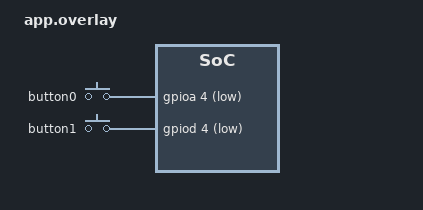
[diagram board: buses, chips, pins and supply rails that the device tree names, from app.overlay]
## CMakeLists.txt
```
# SPDX-License-Identifier: Apache-2.0
cmake_minimum_required(VERSION 3.20.0)
find_package(Zephyr REQUIRED HINTS $ENV{ZEPHYR_BASE})
project(kg100s_lorawan)
zephyr_include_directories(src)
target_sources(app PRIVATE src/main.c src/telemetry.c src/telemetry_packet.c src/join_policy.c
                          src/ble_event.c src/ble_bridge.c)
```

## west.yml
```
# SPDX-License-Identifier: Apache-2.0
manifest:
  version: '1.2'
  projects:
    - name: zephyr
      url: https://github.com/zephyrproject-rtos/zephyr
      revision: 41d10b59730406bbab4ca9f1fbbe9e96aafb4966
      import:
        name-allowlist: [cmsis, cmsis_6, hal_silabs, loramac-node, segger,
                         mbedtls, tf-psa-crypto, tf-psa-crypto-drivers]
  self:
    path: app
```

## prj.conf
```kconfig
# SPDX-License-Identifier: Apache-2.0
CONFIG_LORA=y
CONFIG_LORA_MODULE_BACKEND_LORAMAC_NODE=y
CONFIG_LORAWAN=y
CONFIG_LORAWAN_REGION_US915=y
CONFIG_LORAWAN_NVM_NONE=y

CONFIG_FLASH=y
CONFIG_FLASH_MAP=y
CONFIG_NVS=y
CONFIG_NVS_DATA_CRC=y
CONFIG_SETTINGS=y
CONFIG_SETTINGS_NVS=y
CONFIG_USE_DT_CODE_PARTITION=y

CONFIG_SHELL=y
CONFIG_SHELL_BACKEND_SERIAL=y
CONFIG_SHELL_PROMPT_UART="kg100s> "
CONFIG_SHELL_ECHO_STATUS=n
CONFIG_SHELL_VT100_COLORS=n
CONFIG_SHELL_VT100_COMMANDS=n
CONFIG_SHELL_HISTORY=n
CONFIG_SHELL_CMD_BUFF_SIZE=160
CONFIG_SHELL_STACK_SIZE=3072
CONFIG_LOG=y
CONFIG_LOG_DEFAULT_LEVEL=3
CONFIG_LOG_BACKEND_UART=n
CONFIG_LOG_MODE_IMMEDIATE=y
CONFIG_MAIN_STACK_SIZE=4096
CONFIG_SYSTEM_WORKQUEUE_STACK_SIZE=2048
CONFIG_HEAP_MEM_POOL_SIZE=4096
CONFIG_REBOOT=y
CONFIG_BOOT_BANNER=y
CONFIG_BUILD_OUTPUT_HEX=y
CONFIG_BT=y
CONFIG_BT_PERIPHERAL=y
CONFIG_BT_MAX_CONN=4
CONFIG_BT_SILABS_EFR32_BUFFER_MEMORY=12288
CONFIG_BT_DEVICE_NAME="OpenSidewalk"
CONFIG_BT_DIS=y
CONFIG_BT_DIS_MODEL_NUMBER_STR="KG100S BLE to TTN"
CONFIG_BT_DIS_MANUF_NAME_STR="OpenSidewalk"
CONFIG_SENSOR=y
CONFIG_INPUT=y
CONFIG_INPUT_GPIO_KEYS=y
```

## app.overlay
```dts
/* SPDX-License-Identifier: Apache-2.0 */
/* Standalone application; the factory demo has no MCUboot installation. */
/ {
	chosen {
		zephyr,code-partition = &app_partition;
	};
};

&flash0 {
	partitions {
		/delete-node/ partition@0;
		/delete-node/ partition@c000;
		/delete-node/ partition@82000;

		app_partition: partition@0 {
			compatible = "zephyr,mapped-partition";
			label = "application";
			reg = <0x00000000 0x000f8000>;
		};
		/* Existing 32 KiB storage partition at 0xf8000 holds NVS. */
	};
};

&button0 {
	gpios = <&gpioa 4 (GPIO_ACTIVE_LOW | GPIO_PULL_UP)>;
};

&button1 {
	gpios = <&gpiod 4 (GPIO_ACTIVE_LOW | GPIO_PULL_UP)>;
};
```

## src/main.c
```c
/* SPDX-License-Identifier: Apache-2.0 */
#include <errno.h>
#include <string.h>
#include <zephyr/device.h>
#include <zephyr/kernel.h>
#include <zephyr/lorawan/lorawan.h>
#include <zephyr/settings/settings.h>
#include <zephyr/shell/shell.h>
#include <zephyr/sys/atomic.h>
#include <zephyr/sys/util.h>
#include <zephyr/sys/reboot.h>
#include <zephyr/logging/log.h>
#include "telemetry.h"
#include "join_policy.h"
#include "ble_bridge.h"

LOG_MODULE_REGISTER(kg100s_lorawan, LOG_LEVEL_INF);

struct node_config {
	uint8_t version;
	uint8_t provisioned;
	uint8_t subband;
	uint8_t reserved;
	uint8_t dev_eui[8];
	uint8_t join_eui[8];
	uint8_t app_key[16];
	uint32_t last_nonce;
};

static struct node_config config = {.version = 1, .subband = 2};
static atomic_t ready;
static atomic_t joined;
static atomic_t busy;
static int config_load_error;
static uint16_t telemetry_sequence;
static int64_t next_periodic;
static int64_t telemetry_not_before;
static int64_t next_join;
static unsigned int join_failures;
static int64_t next_ble_attempt;
static atomic_t join_delay_seconds = ATOMIC_INIT(JOIN_BOOT_DELAY_MS / 1000);
K_MUTEX_DEFINE(config_lock);

enum job_kind { JOB_JOIN, JOB_SEND };
struct job {
	enum job_kind kind;
};
K_MSGQ_DEFINE(jobs, sizeof(struct job), 1, 4);

static int config_load(const char *name, size_t len, settings_read_cb read_cb, void *cb_arg)
{
	struct node_config saved;
	int ret;

	if (strcmp(name, "config") != 0) {
		return -ENOENT;
	}
	if (len != sizeof(saved)) {
		return config_load_error = -EINVAL;
	}
	ret = read_cb(cb_arg, &saved, sizeof(saved));
	if (ret != sizeof(saved)) {
		return config_load_error = ret < 0 ? ret : -EIO;
	}
	if (saved.version != 1 || saved.subband < 1 || saved.subband > 8 ||
	    saved.provisioned > 1 || saved.last_nonce > UINT16_MAX) {
		return config_load_error = -EINVAL;
	}
	config = saved;
	return 0;
}
SETTINGS_STATIC_HANDLER_DEFINE(kg100s_node, "kg100s", NULL, config_load, NULL, NULL);

static struct node_config config_snapshot(void)
{
	struct node_config copy;

	k_mutex_lock(&config_lock, K_FOREVER);
	copy = config;
	k_mutex_unlock(&config_lock);
	return copy;
}

static int save_config(const struct node_config *updated)
{
	int ret = settings_save_one("kg100s/config", updated, sizeof(*updated));

	if (ret == 0) {
		k_mutex_lock(&config_lock, K_FOREVER);
		config = *updated;
		k_mutex_unlock(&config_lock);
	}
	return ret;
}

static int cmd_status(const struct shell *sh, size_t argc, char **argv)
{
	struct node_config copy = config_snapshot();
	char dev_eui[17], join_eui[17];

	ARG_UNUSED(argc);
	ARG_UNUSED(argv);
	bin2hex(copy.dev_eui, sizeof(copy.dev_eui), dev_eui, sizeof(dev_eui));
	bin2hex(copy.join_eui, sizeof(copy.join_eui), join_eui, sizeof(join_eui));
	shell_print(sh, "KG100S BLE/LoRaWAN bridge v0.4.1; Zephyr 4.5.0");
	shell_print(sh, "Radio/stack: %s; joined: %s; busy: %s",
		    atomic_get(&ready) ? "ready" : "not ready",
		    atomic_get(&joined) ? "yes" : "no", atomic_get(&busy) ? "yes" : "no");
	shell_print(sh, "US915 sub-band %u: uplink channels %u-%u, 500kHz channel %u",
		    copy.subband, (copy.subband - 1) * 8, copy.subband * 8 - 1,
		    63 + copy.subband);
	shell_print(sh, "OTAA credentials: %s; DevEUI: %s; JoinEUI: %s",
		    copy.provisioned ? "configured" : "not configured", dev_eui, join_eui);
	shell_print(sh, "Last reserved DevNonce: %u; fresh OTAA joins automatically after reboot.",
		    (unsigned int)copy.last_nonce);
	if (atomic_get(&join_delay_seconds) < 0) {
		shell_print(sh, "Auto-join halted by configuration/storage error; check logs.");
	} else {
		shell_print(sh, "Auto-join enabled; last scheduled delay: %u seconds.",
			    (unsigned int)atomic_get(&join_delay_seconds));
	}
	return 0;
}

static int begin_config(const struct shell *sh)
{
	if (!atomic_cas(&busy, 0, 1)) {
		shell_error(sh, "Operation in progress.");
		return -EBUSY;
	}
	if (!atomic_get(&ready) || atomic_get(&joined)) {
		atomic_clear(&busy);
		shell_error(sh, "Radio not ready, operation in progress, or already joined. Reboot before changing a joined profile.");
		return -EBUSY;
	}
	return 0;
}

static int cmd_provision(const struct shell *sh, size_t argc, char **argv)
{
	struct node_config updated;
	uint8_t dev_eui[8], join_eui[8], app_key[16];
	int ret;

	ARG_UNUSED(argc);
	if (strlen(argv[1]) != 16 || strlen(argv[2]) != 16 || strlen(argv[3]) != 32 ||
	    hex2bin(argv[1], 16, dev_eui, 8) != 8 ||
	    hex2bin(argv[2], 16, join_eui, 8) != 8 ||
	    hex2bin(argv[3], 32, app_key, 16) != 16) {
		shell_error(sh, "Expected hexadecimal DevEUI (16), JoinEUI (16), AppKey (32). No colons.");
		return -EINVAL;
	}
	ret = begin_config(sh);
	if (ret) {
		return ret;
	}
	updated = config_snapshot();
	memcpy(updated.dev_eui, dev_eui, sizeof(dev_eui));
	memcpy(updated.join_eui, join_eui, sizeof(join_eui));
	memcpy(updated.app_key, app_key, sizeof(app_key));
	updated.provisioned = 1;
	ret = save_config(&updated);
	atomic_clear(&busy);
	if (ret) {
		shell_error(sh, "Saving credentials failed: %d", ret);
	} else {
		shell_print(sh, "OTAA credentials saved; AppKey is hidden. Register the same values on the network server, then run lw join.");
	}
	return ret;
}

static int cmd_subband(const struct shell *sh, size_t argc, char **argv)
{
	struct node_config updated;
	int ret;

	ARG_UNUSED(argc);
	if (strlen(argv[1]) != 1 || argv[1][0] < '1' || argv[1][0] > '8') {
		shell_error(sh, "Sub-band must be 1 through 8.");
		return -EINVAL;
	}
	ret = begin_config(sh);
	if (ret) {
		return ret;
	}
	updated = config_snapshot();
	updated.subband = argv[1][0] - '0';
	ret = save_config(&updated);
	atomic_clear(&busy);
	if (ret) {
		shell_error(sh, "Saving sub-band failed: %d", ret);
	} else {
		shell_print(sh, "Sub-band %u saved; applied on the next join.", updated.subband);
	}
	return ret;
}

static int cmd_queue(const struct shell *sh, size_t argc, char **argv)
{
	struct job job;
	int ret;

	ARG_UNUSED(argc);
	if (!atomic_cas(&busy, 0, 1)) {
		shell_error(sh, "Operation in progress.");
		return -EBUSY;
	}
	if (!atomic_get(&ready)) {
		shell_error(sh, "Radio/stack is not ready.");
		ret = -ENODEV;
		goto rejected;
	}
	job.kind = strcmp(argv[0], "join") == 0 ? JOB_JOIN : JOB_SEND;
	if (!config_snapshot().provisioned) {
		shell_error(sh, "Configure credentials with lw provision first.");
		ret = -EINVAL;
		goto rejected;
	}
	if (job.kind == JOB_SEND && !atomic_get(&joined)) {
		shell_error(sh, "Join the network first.");
		ret = -ENOTCONN;
		goto rejected;
	}
	if (job.kind == JOB_JOIN && atomic_get(&joined)) {
		shell_error(sh, "Already joined.");
		ret = -EALREADY;
		goto rejected;
	}
	ret = k_msgq_put(&jobs, &job, K_NO_WAIT);
	if (!ret) {
		return 0;
	}
rejected:
	atomic_clear(&busy);
	return ret;
}

static int cmd_sensors(const struct shell *sh, size_t argc, char **argv)
{
	struct telemetry_sample sample;
	int ret;

	ARG_UNUSED(argc);
	ARG_UNUSED(argv);
	ret = telemetry_read(&sample);
	if (ret) {
		return ret;
	}
	shell_print(sh, "MCU die temperature: %d centi-degrees C; BTN0=%u (%u presses), BTN1=%u (%u presses)",
		    sample.temperature_centi_c, !!(sample.buttons & 1), sample.button_presses[0],
		    !!(sample.buttons & 2), sample.button_presses[1]);
	return 0;
}

static int cmd_reboot(const struct shell *sh, size_t argc, char **argv)
{
	ARG_UNUSED(argc);
	ARG_UNUSED(argv);
	if (atomic_get(&busy)) {
		shell_error(sh, "Wait for the current radio/settings operation to finish.");
		return -EBUSY;
	}
	shell_print(sh, "Rebooting; saved credentials and LoRaWAN nonces are retained.");
	k_msleep(100);
	sys_reboot(SYS_REBOOT_COLD);
	return 0;
}

SHELL_STATIC_SUBCMD_SET_CREATE(lw_commands,
	SHELL_CMD_ARG(status, NULL, "Show radio, region, and profile status.", cmd_status, 1, 0),
	SHELL_CMD_ARG(provision, NULL, "<DevEUI> <JoinEUI> <AppKey>, hexadecimal MSB first.", cmd_provision, 4, 0),
	SHELL_CMD_ARG(subband, NULL, "<1-8> Select US915 uplink sub-band.", cmd_subband, 2, 0),
	SHELL_CMD_ARG(join, NULL, "Request one OTAA join; send telemetry if accepted.", cmd_queue, 1, 0),
	SHELL_CMD_ARG(send, NULL, "Send current temperature/button telemetry.", cmd_queue, 1, 0),
	SHELL_CMD_ARG(sensors, NULL, "Read die temperature, button states, and press counts locally.", cmd_sensors, 1, 0),
	SHELL_CMD_ARG(reboot, NULL, "Restart the application.", cmd_reboot, 1, 0),
	SHELL_SUBCMD_SET_END);
SHELL_CMD_REGISTER(lw, &lw_commands, "KG100S LoRaWAN controls", NULL);

static void downlink(uint8_t port, uint8_t flags, int16_t rssi, int8_t snr,
		     uint8_t len, const uint8_t *data)
{
	ARG_UNUSED(flags);
	LOG_INF("Downlink port %u, RSSI %d dBm, SNR %d dB", port, rssi, snr);
	if (len && data) {
		LOG_HEXDUMP_INF(data, len, "Downlink payload");
	}
}

static int send_telemetry(void)
{
	struct telemetry_sample sample;
	uint8_t payload[TELEMETRY_PAYLOAD_SIZE];
	uint16_t sequence = telemetry_sequence + 1;
	int ret;

	/* Clear before sampling so events during TX/RX schedule another update. */
	telemetry_clear_pending();
	ret = telemetry_read(&sample);
	if (!ret) {
		telemetry_pack(payload, sequence, &sample);
		ret = lorawan_send(2, payload, sizeof(payload), LORAWAN_MSG_UNCONFIRMED);
	}
	telemetry_not_before = k_uptime_get() + 10000;
	if (ret) {
		telemetry_request();
		LOG_ERR("Telemetry uplink failed: %d; retry scheduled", ret);
	} else {
		telemetry_sequence = sequence;
		next_periodic = k_uptime_get() + 300000;
		LOG_INF("Telemetry sent seq=%u temp=%d centi-C BTN0=%u/count%u BTN1=%u/count%u",
			sequence, sample.temperature_centi_c, !!(sample.buttons & 1),
			sample.button_presses[0], !!(sample.buttons & 2), sample.button_presses[1]);
	}
	return ret;
}

static int reserve_join_nonce(uint16_t *previous)
{
	struct node_config updated = config_snapshot();
	uint32_t next = updated.last_nonce + 1;
	int ret;

	if (next > UINT16_MAX) {
		return -EOVERFLOW;
	}
	/* Commit before RF TX. A reset during join must never reuse this nonce. */
	*previous = (uint16_t)updated.last_nonce;
	updated.last_nonce = next;
	ret = save_config(&updated);
	if (ret) {
		return ret;
	}
	/* This pinned LoRaMac-node version increments the supplied value for TX. */
	return 0;
}

static void attempt_join(void)
{
	struct node_config profile = config_snapshot();
	uint16_t mask[6] = {0};
	unsigned int first_channel = (profile.subband - 1) * 8;
	struct lorawan_join_config join_cfg = {
		.mode = LORAWAN_ACT_OTAA,
		.dev_eui = profile.dev_eui,
		.otaa = {
			.join_eui = profile.join_eui,
			.app_key = profile.app_key,
			.nwk_key = profile.app_key,
		},
	};
	int ret;

	mask[first_channel / 16] = 0xffu << (first_channel % 16);
	mask[4] = BIT(profile.subband - 1);
	ret = lorawan_set_channels_mask(mask, ARRAY_SIZE(mask));
	if (!ret) {
		ret = reserve_join_nonce(&join_cfg.otaa.dev_nonce);
	}
	if (ret) {
		next_join = -1;
		atomic_set(&join_delay_seconds, -1);
		LOG_ERR("OTAA setup/storage failed: %d; automatic joins halted", ret);
		return;
	}
	LOG_INF("OTAA join: US915 sub-band %u, channels %u-%u, reserved DevNonce %u",
		profile.subband, first_channel, first_channel + 7,
		(unsigned int)join_cfg.otaa.dev_nonce + 1);
	ret = lorawan_join(&join_cfg);
	if (ret) {
		uint32_t delay = join_retry_delay_ms(++join_failures);

		next_join = k_uptime_get() + delay;
		atomic_set(&join_delay_seconds, delay / 1000);
		LOG_WRN("Join failed: %d; retry in %u seconds", ret, delay / 1000);
		return;
	}
	join_failures = 0;
	next_join = -1;
	atomic_set(&join_delay_seconds, 0);
	atomic_set(&joined, 1);
	LOG_INF("LoRaWAN OTAA JOIN ACCEPTED");
	send_telemetry();
}

int main(void)
{
	const struct device *radio = DEVICE_DT_GET(DT_ALIAS(lora0));
	static struct lorawan_downlink_cb callback = {.port = LW_RECV_PORT_ANY, .cb = downlink};
	struct job job;
	bool banner_shown = false;
	int ret;


	LOG_INF("KG100S BLE/LoRaWAN bridge v0.4.1; US915; automatic OTAA");
	if (!device_is_ready(radio)) {
		LOG_ERR("Integrated SX1262 is not ready");
		return -ENODEV;
	}
	ret = telemetry_init();
	if (ret) {
		LOG_ERR("Temperature/button initialization failed: %d", ret);
		return ret;
	}
	ret = settings_subsys_init();
	if (!ret) {
		ret = settings_load_subtree("kg100s");
	}
	/* Settings ignores h_set errors, so explicitly fail closed on our latch. */
	if (!ret) {
		ret = config_load_error;
	}
	if (ret) {
		LOG_ERR("Persistent settings failed: %d; radio transmission disabled", ret);
		return ret;
	}
	ret = lorawan_start();
	if (ret) {
		LOG_ERR("LoRaWAN initialization failed: %d", ret);
		return ret;
	}
	lorawan_register_downlink_callback(&callback);
	lorawan_enable_adr(true);
	atomic_set(&ready, 1);
	ret = ble_bridge_init();
	if (ret) {
		LOG_ERR("Bluetooth initialization failed: %d; LoRaWAN remains available", ret);
	}
	next_join = k_uptime_get() + JOIN_BOOT_DELAY_MS;
	LOG_INF("SX1262 and LoRaWAN ready; automatic join in 3 seconds when provisioned.");

	while (true) {
		if (k_msgq_get(&jobs, &job, K_MSEC(100)) == 0) {
			if (job.kind == JOB_JOIN) {
				attempt_join();
			} else {
				send_telemetry();
			}
			atomic_clear(&busy);
		}
		if (!banner_shown && k_uptime_get() >= JOIN_BOOT_DELAY_MS) {
			printk("\n"
			       "      .  |  .\n"
			       "   ((   /|\\   ))\n"
			       "       /_|_\\\n"
			       "  +-- KG100S --+\n"
			       "  | LoRaWAN TTN |\n"
			       "  +-------------+\n\n");
			banner_shown = true;
		}
		if (join_due(k_uptime_get(), next_join, config_snapshot().provisioned,
			     atomic_get(&joined), atomic_get(&busy)) && atomic_cas(&busy, 0, 1)) {
			attempt_join();
			atomic_clear(&busy);
		}
		if (atomic_get(&joined) && k_uptime_get() >= telemetry_not_before &&
		    (telemetry_pending() || k_uptime_get() >= next_periodic) &&
		    atomic_cas(&busy, 0, 1)) {
			send_telemetry();
			atomic_clear(&busy);
		}
		uint8_t ble_payload[BLE_EVENT_SIZE];

		if (atomic_get(&joined) && k_uptime_get() >= next_ble_attempt &&
		    ble_bridge_pending(ble_payload) && atomic_cas(&busy, 0, 1)) {
			/* The stack can flush pending MAC commands and return -EAGAIN.
			 * Keep our event queued in that case rather than blocking the flush.
			 */
			ret = lorawan_send(3, ble_payload, sizeof(ble_payload), LORAWAN_MSG_UNCONFIRMED);
			ble_bridge_complete(ret == 0);
			next_ble_attempt = k_uptime_get() + 30000;
			if (ret) {
				LOG_WRN("BLE event uplink failed: %d; retained for retry", ret);
			} else {
				LOG_INF("BLE connected event sent on FPort 3, sequence %u",
					(ble_payload[2] << 8) | ble_payload[3]);
			}
			atomic_clear(&busy);
		}
	}
	return 0;
}
```

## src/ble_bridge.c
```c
/* SPDX-License-Identifier: Apache-2.0 */
#include <errno.h>
#include <zephyr/kernel.h>
#include <zephyr/bluetooth/bluetooth.h>
#include <zephyr/bluetooth/conn.h>
#include <zephyr/bluetooth/uuid.h>
#include <zephyr/logging/log.h>
#include <zephyr/shell/shell.h>
#include <zephyr/sys/atomic.h>
#include "ble_bridge.h"

LOG_MODULE_REGISTER(ble_bridge, LOG_LEVEL_INF);

static struct ble_event_queue events;
static struct k_spinlock queue_lock;
static atomic_t enabled;
static atomic_t connected_slots;

static unsigned int connection_count(void)
{
	return __builtin_popcount((unsigned int)atomic_get(&connected_slots));
}

static const struct bt_data advertising[] = {
	BT_DATA_BYTES(BT_DATA_FLAGS, BT_LE_AD_GENERAL | BT_LE_AD_NO_BREDR),
	BT_DATA_BYTES(BT_DATA_UUID16_ALL, BT_UUID_16_ENCODE(BT_UUID_DIS_VAL)),
};
static const struct bt_data scan_response[] = {
	BT_DATA(BT_DATA_NAME_COMPLETE, CONFIG_BT_DEVICE_NAME, sizeof(CONFIG_BT_DEVICE_NAME) - 1),
};

static void advertise(struct k_work *work);
K_WORK_DELAYABLE_DEFINE(advertise_work, advertise);

static void advertise(struct k_work *work)
{
	ARG_UNUSED(work);
	if (!atomic_get(&enabled) || connection_count() >= CONFIG_BT_MAX_CONN) {
		return;
	}
	int ret = bt_le_adv_start(BT_LE_ADV_CONN_FAST_1, advertising, ARRAY_SIZE(advertising),
				 scan_response, ARRAY_SIZE(scan_response));

	if (ret && ret != -EALREADY) {
		LOG_WRN("BLE advertising failed: %d; retry in one second", ret);
		k_work_reschedule(&advertise_work, K_SECONDS(1));
	} else {
		LOG_INF("BLE advertising as %s", CONFIG_BT_DEVICE_NAME);
	}
}

static void connected(struct bt_conn *conn, uint8_t error)
{
	if (error) {
		LOG_WRN("BLE connection failed: 0x%02x", error);
		return;
	}
	const bt_addr_le_t *peer = bt_conn_get_dst(conn);
	char address[BT_ADDR_LE_STR_LEN];
	k_spinlock_key_t key = k_spin_lock(&queue_lock);
	bool queued = ble_event_push(&events, peer->type, peer->a.val);

	k_spin_unlock(&queue_lock, key);
	atomic_set_bit(&connected_slots, bt_conn_index(conn));
	bt_addr_le_to_str(peer, address, sizeof(address));
	if (queued) {
		LOG_INF("BLE connected %s; TTN event queued", address);
	} else {
		LOG_WRN("BLE connected %s; event dropped (queue full/address unsupported)", address);
	}
	/* The controller stops this advertising set on every new connection.
	 * Defer restarting it until after the callback, while slots remain.
	 */
	k_work_reschedule(&advertise_work, K_NO_WAIT);
}

static void disconnected(struct bt_conn *conn, uint8_t reason)
{
	/* An immediate link failure can produce disconnected without a prior
	 * successful connected callback. Clear only this connection's slot.
	 */
	atomic_clear_bit(&connected_slots, bt_conn_index(conn));
	LOG_INF("BLE disconnected: 0x%02x", reason);
}

static void recycled(void)
{
	/* The connection slot is available again; no RF work runs in callbacks. */
	k_work_reschedule(&advertise_work, K_NO_WAIT);
}

BT_CONN_CB_DEFINE(bridge_connections) = {
	.connected = connected,
	.disconnected = disconnected,
	.recycled = recycled,
};

bool ble_bridge_pending(uint8_t payload[BLE_EVENT_SIZE])
{
	k_spinlock_key_t key = k_spin_lock(&queue_lock);
	bool pending = ble_event_peek(&events, payload);

	k_spin_unlock(&queue_lock, key);
	return pending;
}

void ble_bridge_complete(bool success)
{
	k_spinlock_key_t key = k_spin_lock(&queue_lock);

	ble_event_complete(&events, success);
	k_spin_unlock(&queue_lock, key);
}

static int cmd_status(const struct shell *sh, size_t argc, char **argv)
{
	ARG_UNUSED(argc);
	ARG_UNUSED(argv);
	k_spinlock_key_t key = k_spin_lock(&queue_lock);
	unsigned int count = events.count;
	uint32_t dropped = events.dropped;
	uint32_t sent = events.sent;

	k_spin_unlock(&queue_lock, key);
	shell_print(sh, "BLE %s; name: %s; connections: %u/%u; queued: %u/8; sent: %u; dropped: %u",
		    atomic_get(&enabled) ? "enabled" : "disabled", CONFIG_BT_DEVICE_NAME,
		    connection_count(), CONFIG_BT_MAX_CONN,
		    count, sent, dropped);
	shell_print(sh, "Connections generate FPort 3 events; 30 seconds between attempts; RAM queue.");
	return 0;
}

SHELL_STATIC_SUBCMD_SET_CREATE(ble_commands,
	SHELL_CMD_ARG(status, NULL, "Show BLE connection and TTN event queue.", cmd_status, 1, 0),
	SHELL_SUBCMD_SET_END);
SHELL_CMD_REGISTER(ble, &ble_commands, "BLE connection bridge", NULL);

int ble_bridge_init(void)
{
	int ret = bt_enable(NULL);

	if (ret) {
		return ret;
	}
	atomic_set(&enabled, 1);
	k_work_reschedule(&advertise_work, K_NO_WAIT);
	return 0;
}
```

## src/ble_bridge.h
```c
/* SPDX-License-Identifier: Apache-2.0 */
#ifndef BLE_BRIDGE_H
#define BLE_BRIDGE_H

#include "ble_event.h"

int ble_bridge_init(void);
bool ble_bridge_pending(uint8_t payload[BLE_EVENT_SIZE]);
void ble_bridge_complete(bool success);

#endif
```

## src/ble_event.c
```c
/* SPDX-License-Identifier: Apache-2.0 */
#include <string.h>
#include "ble_event.h"

bool ble_event_push(struct ble_event_queue *queue, uint8_t type, const uint8_t address_le[6])
{
	if (queue->count == BLE_EVENT_CAPACITY || type > 3) {
		queue->dropped++;
		return false;
	}
	uint8_t *out = queue->payloads[(queue->head + queue->count) % BLE_EVENT_CAPACITY];
	uint16_t sequence = ++queue->sequence;

	out[0] = 1;
	out[1] = 1; /* Connected. */
	out[2] = sequence >> 8;
	out[3] = sequence;
	out[4] = type & 1; /* Normalize public/random identity address types. */
	for (unsigned int i = 0; i < 6; i++) {
		out[5 + i] = address_le[5 - i];
	}
	queue->count++;
	return true;
}

bool ble_event_peek(const struct ble_event_queue *queue, uint8_t out[BLE_EVENT_SIZE])
{
	if (queue->count == 0) {
		return false;
	}
	memcpy(out, queue->payloads[queue->head], BLE_EVENT_SIZE);
	return true;
}

void ble_event_complete(struct ble_event_queue *queue, bool success)
{
	if (success && queue->count) {
		queue->head = (queue->head + 1) % BLE_EVENT_CAPACITY;
		queue->count--;
		queue->sent++;
	}
}
```

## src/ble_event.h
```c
/* SPDX-License-Identifier: Apache-2.0 */
#ifndef BLE_EVENT_H
#define BLE_EVENT_H

#include <stdbool.h>
#include <stdint.h>

#define BLE_EVENT_SIZE 11
#define BLE_EVENT_CAPACITY 8

/* Caller serializes access. Events stay queued until a successful send. */
struct ble_event_queue {
	uint8_t payloads[BLE_EVENT_CAPACITY][BLE_EVENT_SIZE];
	uint8_t head;
	uint8_t count;
	uint16_t sequence;
	uint32_t dropped;
	uint32_t sent;
};

bool ble_event_push(struct ble_event_queue *queue, uint8_t type, const uint8_t address_le[6]);
bool ble_event_peek(const struct ble_event_queue *queue, uint8_t out[BLE_EVENT_SIZE]);
void ble_event_complete(struct ble_event_queue *queue, bool success);

#endif
```

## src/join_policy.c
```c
/* SPDX-License-Identifier: Apache-2.0 */
#include "join_policy.h"

uint32_t join_retry_delay_ms(unsigned int failures)
{
	if (failures >= 5) {
		return 900000;
	}
	return 60000u << (failures > 0 ? failures - 1 : 0);
}

bool join_due(int64_t now, int64_t due, bool provisioned, bool joined, bool busy)
{
	return provisioned && !joined && !busy && due >= 0 && now >= due;
}
```

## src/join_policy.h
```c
/* SPDX-License-Identifier: Apache-2.0 */
#ifndef KG100S_JOIN_POLICY_H
#define KG100S_JOIN_POLICY_H
#include <stdbool.h>
#include <stdint.h>

#define JOIN_BOOT_DELAY_MS 3000
uint32_t join_retry_delay_ms(unsigned int failures);
bool join_due(int64_t now, int64_t due, bool provisioned, bool joined, bool busy);
#endif
```

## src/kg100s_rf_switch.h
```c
/* SPDX-License-Identifier: Apache-2.0
 * Copyright 2026 Kentucky Open Science contributors
 * Hardware reference: Semtech SX1261/2 datasheet rev 2.2, section 8.6.
 */
#ifndef OPENSIDEWALK_KG100S_RF_SWITCH_H
#define OPENSIDEWALK_KG100S_RF_SWITCH_H
#include <stdint.h>
#include <stddef.h>

/* Reapply after sleep; preserve every bit outside each documented field. */
static inline void kg100s_rf_switch_restore(uint8_t (*read_reg)(uint16_t),
					  void (*write_reg)(uint16_t, uint8_t))
{
	static const struct {
		uint16_t address;
		uint8_t mask;
		uint8_t value;
	} fields[] = {
		{0x0580, 0x08, 0x08},
		{0x0583, 0x08, 0x00},
		{0x0584, 0x08, 0x00},
		{0x0585, 0x08, 0x00},
		{0x0920, 0x0f, 0x0e}, /* voltage selection 6, output level high */
	};

	for (size_t i = 0; i < sizeof(fields) / sizeof(fields[0]); ++i) {
		uint8_t old = read_reg(fields[i].address);

		write_reg(fields[i].address, (old & (uint8_t)~fields[i].mask) | fields[i].value);
	}
}
#endif
```

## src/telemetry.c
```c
/* SPDX-License-Identifier: Apache-2.0 */
#include <errno.h>
#include <zephyr/device.h>
#include <zephyr/drivers/gpio.h>
#include <zephyr/drivers/sensor.h>
#include <zephyr/input/input.h>
#include <zephyr/kernel.h>
#include <zephyr/sys/atomic.h>
#include <zephyr/logging/log.h>
#include "telemetry.h"

LOG_MODULE_REGISTER(kg100s_telemetry, LOG_LEVEL_INF);

static const struct device *const temperature = DEVICE_DT_GET(DT_ALIAS(die_temp0));
static const struct gpio_dt_spec buttons[] = {
	GPIO_DT_SPEC_GET(DT_ALIAS(sw0), gpios),
	GPIO_DT_SPEC_GET(DT_ALIAS(sw1), gpios),
};
static atomic_t presses[2];
static atomic_t pending;
K_MUTEX_DEFINE(temperature_lock);

static void button_event(struct input_event *evt, void *user_data)
{
	unsigned int index;

	ARG_UNUSED(user_data);
	if (evt->type != INPUT_EV_KEY || (evt->code != INPUT_KEY_0 && evt->code != INPUT_KEY_1)) {
		return;
	}
	index = evt->code == INPUT_KEY_0 ? 0 : 1;
	if (evt->value) {
		atomic_inc(&presses[index]);
	}
	atomic_set(&pending, 1);
	LOG_INF("BTN%u %s, presses=%u", index, evt->value ? "pressed" : "released",
		(unsigned int)(uint16_t)atomic_get(&presses[index]));
}
INPUT_CALLBACK_DEFINE(DEVICE_DT_GET(DT_PATH(buttons)), button_event, NULL);

int telemetry_init(void)
{
	if (!device_is_ready(temperature)) {
		return -ENODEV;
	}
	for (size_t i = 0; i < ARRAY_SIZE(buttons); i++) {
		if (!gpio_is_ready_dt(&buttons[i])) {
			return -ENODEV;
		}
	}
	return 0;
}

int telemetry_read(struct telemetry_sample *sample)
{
	struct sensor_value value;
	int ret;

	sample->temperature_centi_c = TELEMETRY_TEMPERATURE_UNAVAILABLE;
	k_mutex_lock(&temperature_lock, K_FOREVER);
	ret = sensor_sample_fetch_chan(temperature, SENSOR_CHAN_DIE_TEMP);
	if (!ret) {
		ret = sensor_channel_get(temperature, SENSOR_CHAN_DIE_TEMP, &value);
	}
	k_mutex_unlock(&temperature_lock);
	if (!ret) {
		int64_t centi = (int64_t)value.val1 * 100 + value.val2 / 10000;

		if (centi > INT16_MIN && centi <= INT16_MAX) {
			sample->temperature_centi_c = centi;
		}
	} else {
		LOG_WRN("Die temperature read failed: %d", ret);
	}
	sample->buttons = 0;
	for (size_t i = 0; i < ARRAY_SIZE(buttons); i++) {
		ret = gpio_pin_get_dt(&buttons[i]);
		if (ret < 0) {
			return ret;
		}
		if (ret) {
			sample->buttons |= BIT(i);
		}
		sample->button_presses[i] = (uint16_t)atomic_get(&presses[i]);
	}
	return 0;
}

bool telemetry_pending(void)
{
	return atomic_get(&pending) != 0;
}

void telemetry_clear_pending(void)
{
	atomic_clear(&pending);
}

void telemetry_request(void)
{
	atomic_set(&pending, 1);
}
```

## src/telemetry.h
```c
/* SPDX-License-Identifier: Apache-2.0 */
#ifndef KG100S_TELEMETRY_H
#define KG100S_TELEMETRY_H

#include <stdbool.h>
#include "telemetry_packet.h"

int telemetry_init(void);
int telemetry_read(struct telemetry_sample *sample);
bool telemetry_pending(void);
void telemetry_clear_pending(void);
void telemetry_request(void);

#endif
```

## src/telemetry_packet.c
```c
/* SPDX-License-Identifier: Apache-2.0 */
#include "telemetry_packet.h"

void telemetry_pack(uint8_t out[TELEMETRY_PAYLOAD_SIZE], uint16_t sequence,
		    const struct telemetry_sample *sample)
{
	uint16_t temp = (uint16_t)sample->temperature_centi_c;

	out[0] = 1;
	out[1] = sequence >> 8;
	out[2] = sequence;
	out[3] = temp >> 8;
	out[4] = temp;
	out[5] = sample->buttons & 3;
	out[6] = sample->button_presses[0] >> 8;
	out[7] = sample->button_presses[0];
	out[8] = sample->button_presses[1] >> 8;
	out[9] = sample->button_presses[1];
}
```

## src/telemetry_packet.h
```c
/* SPDX-License-Identifier: Apache-2.0 */
#ifndef KG100S_TELEMETRY_PACKET_H
#define KG100S_TELEMETRY_PACKET_H

#include <stdint.h>

#define TELEMETRY_PAYLOAD_SIZE 10
#define TELEMETRY_TEMPERATURE_UNAVAILABLE INT16_MIN

struct telemetry_sample {
	int16_t temperature_centi_c;
	uint8_t buttons;
	uint16_t button_presses[2];
};

void telemetry_pack(uint8_t out[TELEMETRY_PAYLOAD_SIZE], uint16_t sequence,
		    const struct telemetry_sample *sample);

#endif
```
